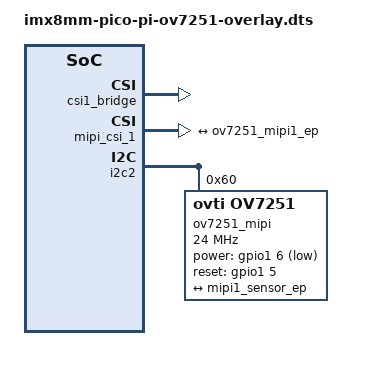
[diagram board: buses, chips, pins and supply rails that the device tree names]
// SPDX-License-Identifier: (GPL-2.0+ OR MIT)
/*
 * Copyright 2020 TechNexion Ltd.
 *
 * Author: Richard Hu <richard.hu@technexion.com>
 *
 */

/dts-v1/;
/plugin/;

#include <dt-bindings/interrupt-controller/irq.h>
#include <dt-bindings/clock/imx8mm-clock.h>
#include <dt-bindings/gpio/gpio.h>

/ {
	fragment@0 {
		target = <&csi1_bridge>;
		__overlay__ {
			status = "okay";
		};
	};

	fragment@1 {
		target = <&mipi_csi_1>;
		__overlay__ {
			status = "okay";
			#address-cells = <1>;
			#size-cells = <0>;

			port {
				mipi1_sensor_ep: endpoint@1 {
					remote-endpoint = <&ov7251_mipi1_ep>;
					data-lanes = <1>;
					csis-hs-settle = <13>;
					csis-clk-settle = <2>;
					csis-wclk;
				};
			};
		};
	};

	fragment@2 {
		target = <&i2c2>;
		__overlay__ {
			#address-cells = <1>;
			#size-cells = <0>;
			status = "okay";

			ov7251_mipi: ov7251_mipi@60 {
				compatible = "ovti,ov7251";
				reg = <0x60>;
				status = "okay";
				pinctrl-names = "default";
				pinctrl-0 = <&pinctrl_csi_pwn>, <&pinctrl_csi_rst>;
				clocks = <&clk IMX8MM_CLK_CLKO1>;
				clock-names = "xclk";
				clock-frequency = <24000000>;

				csi_id = <0>;
				power-gpios = <&gpio1 6 GPIO_ACTIVE_LOW>;
				reset-gpios = <&gpio1 5 GPIO_ACTIVE_HIGH>;

				port {
					ov7251_mipi1_ep: endpoint {
						data-lanes = <0>;
						remote-endpoint = <&mipi1_sensor_ep>;
					};
				};
			};
		};
	};
};
